AUTOSAR XML (schema 4-2-2)
package /STELLANTIS/EPT/ASWCs
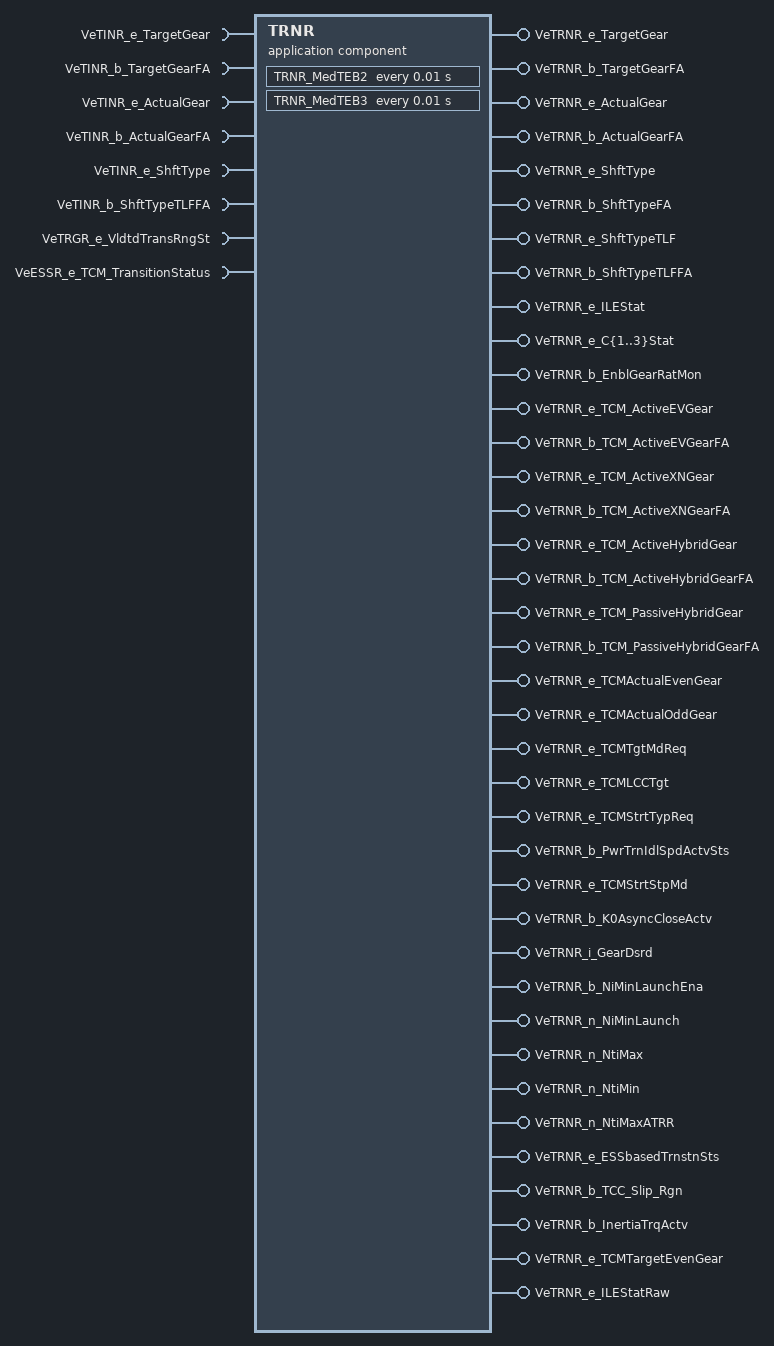
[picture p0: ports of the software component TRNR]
  application sw component type TRNR
    8 x require port:
      VeTINR_e_TargetGear: variation-point={short-label=vpVeTINR_e_TargetGear, sw-syscond=1}, nonqueued-receiver-com-spec{data-element=Value, init-value=CeTRNR_e_Neutral}, required-interface=VeTINR_e_TargetGear
      VeTINR_b_TargetGearFA: variation-point={short-label=vpVeTINR_b_TargetGearFA, sw-syscond=1}, nonqueued-receiver-com-spec{data-element=Value, init-value=0}, required-interface=VeTINR_b_TargetGearFA
      VeTINR_e_ActualGear: variation-point={short-label=vpVeTINR_e_ActualGear, sw-syscond=1}, nonqueued-receiver-com-spec{data-element=Value, init-value=CeTRNR_e_Neutral}, required-interface=VeTINR_e_ActualGear
      VeTINR_b_ActualGearFA: variation-point={short-label=vpVeTINR_b_ActualGearFA, sw-syscond=1}, nonqueued-receiver-com-spec{data-element=Value, init-value=0}, required-interface=VeTINR_b_ActualGearFA
      VeTINR_e_ShftType: variation-point={short-label=vpVeTINR_e_ShftType, sw-syscond=1}, nonqueued-receiver-com-spec{data-element=Value, init-value=CeTRNR_e_SteadyState}, required-interface=VeTINR_e_ShftType
      VeTINR_b_ShftTypeTLFFA: nonqueued-receiver-com-spec{data-element=Value, init-value=0}, required-interface=VeTINR_b_ShftTypeTLFFA
      VeTRGR_e_VldtdTransRngSt: variation-point={short-label=vpVeTRGR_e_VldtdTransRngSt, sw-syscond=1}, nonqueued-receiver-com-spec{data-element=Value, init-value=CeTRGR_e_NoSelectionAvailable}, required-interface=VeTRGR_e_VldtdTransRngSt
      VeESSR_e_TCM_TransitionStatus: nonqueued-receiver-com-spec{data-element=Value, init-value=CeESSR_e_Trans_Stat_Off}, required-interface=VeESSR_e_TCM_TransitionStatus
    40 x provide port:
      VeTRNR_e_TargetGear: nonqueued-sender-com-spec{data-element=Value, init-value=CeTRNR_e_Neutral}, provided-interface=VeTRNR_e_TargetGear
      VeTRNR_b_TargetGearFA: nonqueued-sender-com-spec{data-element=Value, init-value=0}, provided-interface=VeTRNR_b_TargetGearFA
      VeTRNR_e_ActualGear: nonqueued-sender-com-spec{data-element=Value, init-value=CeTRNR_e_Neutral}, provided-interface=VeTRNR_e_ActualGear
      VeTRNR_b_ActualGearFA: nonqueued-sender-com-spec{data-element=Value, init-value=0}, provided-interface=VeTRNR_b_ActualGearFA
      VeTRNR_e_ShftType: nonqueued-sender-com-spec{data-element=Value, init-value=CeTRNR_e_SteadyState}, provided-interface=VeTRNR_e_ShftType
      VeTRNR_b_ShftTypeFA: nonqueued-sender-com-spec{data-element=Value, init-value=0}, provided-interface=VeTRNR_b_ShftTypeFA
      VeTRNR_e_ShftTypeTLF: nonqueued-sender-com-spec{data-element=Value, init-value=CeTRNR_e_SteadyStateDCT}, provided-interface=VeTRNR_e_ShftTypeTLF
      VeTRNR_b_ShftTypeTLFFA: nonqueued-sender-com-spec{data-element=Value, init-value=0}, provided-interface=VeTRNR_b_ShftTypeTLFFA
      VeTRNR_e_ILEStat: nonqueued-sender-com-spec{data-element=Value, init-value=CeHCCR_e_ClInvalid}, provided-interface=VeTRNR_e_ILEStat
      VeTRNR_e_C{1..3}Stat: nonqueued-sender-com-spec{data-element=Value, init-value=CeHCCR_e_ClInvalid}, provided-interface=VeTRNR_e_C{1..3}Stat
      VeTRNR_b_EnblGearRatMon: nonqueued-sender-com-spec{data-element=Value, init-value=0}, provided-interface=VeTRNR_b_EnblGearRatMon
      VeTRNR_e_TCM_ActiveEVGear: nonqueued-sender-com-spec{data-element=Value, init-value=CeTRNR_e_Neutral}, provided-interface=VeTRNR_e_TCM_ActiveEVGear
      VeTRNR_b_TCM_ActiveEVGearFA: nonqueued-sender-com-spec{data-element=Value, init-value=0}, provided-interface=VeTRNR_b_TCM_ActiveEVGearFA
      VeTRNR_e_TCM_ActiveXNGear: nonqueued-sender-com-spec{data-element=Value, init-value=CeTRNR_e_Neutral}, provided-interface=VeTRNR_e_TCM_ActiveXNGear
      VeTRNR_b_TCM_ActiveXNGearFA: nonqueued-sender-com-spec{data-element=Value, init-value=0}, provided-interface=VeTRNR_b_TCM_ActiveXNGearFA
      VeTRNR_e_TCM_ActiveHybridGear: nonqueued-sender-com-spec{data-element=Value, init-value=CeTRNR_e_Neutral}, provided-interface=VeTRNR_e_TCM_ActiveHybridGear
      VeTRNR_b_TCM_ActiveHybridGearFA: nonqueued-sender-com-spec{data-element=Value, init-value=0}, provided-interface=VeTRNR_b_TCM_ActiveHybridGearFA
      VeTRNR_e_TCM_PassiveHybridGear: nonqueued-sender-com-spec{data-element=Value, init-value=CeTRNR_e_Neutral}, provided-interface=VeTRNR_e_TCM_PassiveHybridGear
      VeTRNR_b_TCM_PassiveHybridGearFA: nonqueued-sender-com-spec{data-element=Value, init-value=0}, provided-interface=VeTRNR_b_TCM_PassiveHybridGearFA
      VeTRNR_e_TCMActualEvenGear: nonqueued-sender-com-spec{data-element=Value, init-value=CeTRNR_e_Neutral}, provided-interface=VeTRNR_e_TCMActualEvenGear
      VeTRNR_e_TCMActualOddGear: nonqueued-sender-com-spec{data-element=Value, init-value=CeTRNR_e_Neutral}, provided-interface=VeTRNR_e_TCMActualOddGear
      VeTRNR_e_TCMTgtMdReq: nonqueued-sender-com-spec{data-element=Value, init-value=CeTRNR_e_SerEngOff}, provided-interface=VeTRNR_e_TCMTgtMdReq
      VeTRNR_e_TCMLCCTgt: nonqueued-sender-com-spec{data-element=Value, init-value=CeTMMR_e_ClchUnlock}, provided-interface=VeTRNR_e_TCMLCCTgt
      VeTRNR_e_TCMStrtTypReq: nonqueued-sender-com-spec{data-element=Value, init-value=CeTRNR_e_NormalStrt}, provided-interface=VeTRNR_e_TCMStrtTypReq
      VeTRNR_b_PwrTrnIdlSpdActvSts: nonqueued-sender-com-spec{data-element=Value, init-value=0}, provided-interface=VeTRNR_b_PwrTrnIdlSpdActvSts
      VeTRNR_e_TCMStrtStpMd: nonqueued-sender-com-spec{data-element=Value, init-value=CeTRNR_e_TCMStrtStpMd_inactv}, provided-interface=VeTRNR_e_TCMStrtStpMd
      VeTRNR_b_K0AsyncCloseActv: nonqueued-sender-com-spec{data-element=Value, init-value=0}, provided-interface=VeTRNR_b_K0AsyncCloseActv
      VeTRNR_i_GearDsrd: nonqueued-sender-com-spec{data-element=Value, init-value=0}, provided-interface=VeTRNR_i_GearDsrd
      VeTRNR_b_NiMinLaunchEna: nonqueued-sender-com-spec{data-element=Value, init-value=0}, provided-interface=VeTRNR_b_NiMinLaunchEna
      VeTRNR_n_NiMinLaunch: nonqueued-sender-com-spec{data-element=Value, init-value=0}, provided-interface=VeTRNR_n_NiMinLaunch
      VeTRNR_n_NtiMax: nonqueued-sender-com-spec{data-element=Value, init-value=0}, provided-interface=VeTRNR_n_NtiMax
      VeTRNR_n_NtiMin: nonqueued-sender-com-spec{data-element=Value, init-value=0}, provided-interface=VeTRNR_n_NtiMin
      VeTRNR_n_NtiMaxATRR: nonqueued-sender-com-spec{data-element=Value, init-value=0}, provided-interface=VeTRNR_n_NtiMaxATRR
      VeTRNR_e_ESSbasedTrnstnSts: nonqueued-sender-com-spec{data-element=Value, init-value=CeESSR_e_Trans_Stat_Off}, provided-interface=VeTRNR_e_ESSbasedTrnstnSts
      VeTRNR_b_TCC_Slip_Rgn: nonqueued-sender-com-spec{data-element=Value, init-value=0}, provided-interface=VeTRNR_b_TCC_Slip_Rgn
      VeTRNR_b_InertiaTrqActv: nonqueued-sender-com-spec{data-element=Value, init-value=0}, provided-interface=VeTRNR_b_InertiaTrqActv
      VeTRNR_e_TCMTargetEvenGear: nonqueued-sender-com-spec{data-element=Value, init-value=CeTRNR_e_Neutral}, provided-interface=VeTRNR_e_TCMTargetEvenGear
      VeTRNR_e_ILEStatRaw: nonqueued-sender-com-spec{data-element=Value, init-value=CeHCCR_e_ClInvalid}, provided-interface=VeTRNR_e_ILEStatRaw
    behavior IB_TRNR: data-type-mapping=msADTtoIDTMapping, handle-termination-and-restart=NO-SUPPORT, included-data-type-set=data-type=rt_Array_TeTRNR_e_TCMGearStat_4
      timing event Event_MedTEB2: start-on-event=TRNR_MedTEB2, period=0.01
      timing event Event_MedTEB3: start-on-event=TRNR_MedTEB3, period=0.01
      init event Event_TRNR_ac_Init: start-on-event=TRNR_ac_Init
      init event Event_PwrOn: start-on-event=TRNR_PwrOn
      explicit-inter-runnable-variables:
        data TRNC_C2_StatInternal_IRV: category=VALUE, sw-calibration-access=READ-ONLY, type=TeHCCR_e_ClutchStatus, init-value=CeHCCR_e_ClInvalid
      4 x runnable:
        TRNR_ac_Init
          data-send-points:
            22 x access:
              OUT_VeTRNR_b_TCC_Slip_Rgn_Value: accessed-variable=VeTRNR_b_TCC_Slip_Rgn.Value
              OUT_VeTRNR_e_TargetGear_Value: accessed-variable=VeTRNR_e_TargetGear.Value
              OUT_VeTRNR_e_ActualGear_Value: accessed-variable=VeTRNR_e_ActualGear.Value
              OUT_VeTRNR_e_ShftType_Value: accessed-variable=VeTRNR_e_ShftType.Value
              OUT_VeTRNR_e_ShftTypeTLF_Value: accessed-variable=VeTRNR_e_ShftTypeTLF.Value
              OUT_VeTRNR_e_ILEStat_Value: accessed-variable=VeTRNR_e_ILEStat.Value
              OUT_VeTRNR_e_C{1..3}Stat_Value: accessed-variable=VeTRNR_e_C{1..3}Stat.Value
              OUT_VeTRNR_e_TCM_ActiveEVGear_Value: accessed-variable=VeTRNR_e_TCM_ActiveEVGear.Value
              OUT_VeTRNR_e_TCM_ActiveXNGear_Value: accessed-variable=VeTRNR_e_TCM_ActiveXNGear.Value
              OUT_VeTRNR_e_TCM_ActiveHybridGear_Value: accessed-variable=VeTRNR_e_TCM_ActiveHybridGear.Value
              OUT_VeTRNR_e_TCM_PassiveHybridGear_Value: accessed-variable=VeTRNR_e_TCM_PassiveHybridGear.Value
              OUT_VeTRNR_e_TCMActualEvenGear_Value: accessed-variable=VeTRNR_e_TCMActualEvenGear.Value
              OUT_VeTRNR_e_TCMActualOddGear_Value: accessed-variable=VeTRNR_e_TCMActualOddGear.Value
              OUT_VeTRNR_e_TCMTgtMdReq_Value: accessed-variable=VeTRNR_e_TCMTgtMdReq.Value
              OUT_VeTRNR_e_TCMLCCTgt_Value: accessed-variable=VeTRNR_e_TCMLCCTgt.Value
              OUT_VeTRNR_e_TCMStrtTypReq_Value: accessed-variable=VeTRNR_e_TCMStrtTypReq.Value
              OUT_VeTRNR_e_TCMStrtStpMd_Value: accessed-variable=VeTRNR_e_TCMStrtStpMd.Value
              OUT_VeTRNR_e_ESSbasedTrnstnSts_Value: accessed-variable=VeTRNR_e_ESSbasedTrnstnSts.Value
              OUT_VeTRNR_e_TCMTargetEvenGear_Value: accessed-variable=VeTRNR_e_TCMTargetEvenGear.Value
              OUT_VeTRNR_e_ILEStatRaw_Value: accessed-variable=VeTRNR_e_ILEStatRaw.Value
        TRNR_PwrOn
          data-send-points:
            40 x access:
              OUT_VeTRNR_e_C2Stat_Value: accessed-variable=VeTRNR_e_C2Stat.Value
              OUT_VeTRNR_b_TargetGearFA_Value: accessed-variable=VeTRNR_b_TargetGearFA.Value
              OUT_VeTRNR_b_ActualGearFA_Value: accessed-variable=VeTRNR_b_ActualGearFA.Value
              OUT_VeTRNR_i_GearDsrd_Value: accessed-variable=VeTRNR_i_GearDsrd.Value
              OUT_VeTRNR_b_NiMinLaunchEna_Value: accessed-variable=VeTRNR_b_NiMinLaunchEna.Value
              OUT_VeTRNR_n_NiMinLaunch_Value: accessed-variable=VeTRNR_n_NiMinLaunch.Value
              OUT_VeTRNR_e_TCMLCCTgt_Value: accessed-variable=VeTRNR_e_TCMLCCTgt.Value
              OUT_VeTRNR_e_ActualGear_Value: accessed-variable=VeTRNR_e_ActualGear.Value
              OUT_VeTRNR_e_TargetGear_Value: accessed-variable=VeTRNR_e_TargetGear.Value
              OUT_VeTRNR_e_ShftType_Value: accessed-variable=VeTRNR_e_ShftType.Value
              OUT_VeTRNR_n_NtiMax_Value: accessed-variable=VeTRNR_n_NtiMax.Value
              OUT_VeTRNR_e_C1Stat_Value: accessed-variable=VeTRNR_e_C1Stat.Value
              OUT_VeTRNR_n_NtiMin_Value: accessed-variable=VeTRNR_n_NtiMin.Value
              OUT_VeTRNR_b_ShftTypeFA_Value: accessed-variable=VeTRNR_b_ShftTypeFA.Value
              OUT_VeTRNR_e_ILEStat_Value: accessed-variable=VeTRNR_e_ILEStat.Value
              OUT_VeTRNR_b_K0AsyncCloseActv_Value: accessed-variable=VeTRNR_b_K0AsyncCloseActv.Value
              OUT_VeTRNR_b_EnblGearRatMon_Value: accessed-variable=VeTRNR_b_EnblGearRatMon.Value
              OUT_VeTRNR_b_TCM_ActiveEVGearFA_Value: accessed-variable=VeTRNR_b_TCM_ActiveEVGearFA.Value
              OUT_VeTRNR_e_TCM_ActiveHybridGear_Value: accessed-variable=VeTRNR_e_TCM_ActiveHybridGear.Value
              OUT_VeTRNR_e_TCM_ActiveEVGear_Value: accessed-variable=VeTRNR_e_TCM_ActiveEVGear.Value
              OUT_VeTRNR_e_TCM_ActiveXNGear_Value: accessed-variable=VeTRNR_e_TCM_ActiveXNGear.Value
              OUT_VeTRNR_e_TCM_PassiveHybridGear_Value: accessed-variable=VeTRNR_e_TCM_PassiveHybridGear.Value
              OUT_VeTRNR_e_C3Stat_Value: accessed-variable=VeTRNR_e_C3Stat.Value
              OUT_VeTRNR_b_TCM_ActiveXNGearFA_Value: accessed-variable=VeTRNR_b_TCM_ActiveXNGearFA.Value
              OUT_VeTRNR_b_TCM_ActiveHybridGearFA_Value: accessed-variable=VeTRNR_b_TCM_ActiveHybridGearFA.Value
              OUT_VeTRNR_b_TCM_PassiveHybridGearFA_Value: accessed-variable=VeTRNR_b_TCM_PassiveHybridGearFA.Value
              OUT_VeTRNR_e_ESSbasedTrnstnSts_Value: accessed-variable=VeTRNR_e_ESSbasedTrnstnSts.Value
              OUT_VeTRNR_e_TCMActualEvenGear_Value: accessed-variable=VeTRNR_e_TCMActualEvenGear.Value
              OUT_VeTRNR_e_TCMActualOddGear_Value: accessed-variable=VeTRNR_e_TCMActualOddGear.Value
              OUT_VeTRNR_n_NtiMaxATRR_Value: accessed-variable=VeTRNR_n_NtiMaxATRR.Value
              OUT_VeTRNR_b_InertiaTrqActv_Value: accessed-variable=VeTRNR_b_InertiaTrqActv.Value
              OUT_VeTRNR_e_TCMTargetEvenGear_Value: accessed-variable=VeTRNR_e_TCMTargetEvenGear.Value
              OUT_VeTRNR_e_TCMTgtMdReq_Value: accessed-variable=VeTRNR_e_TCMTgtMdReq.Value
              OUT_VeTRNR_e_TCMStrtTypReq_Value: accessed-variable=VeTRNR_e_TCMStrtTypReq.Value
              OUT_VeTRNR_b_PwrTrnIdlSpdActvSts_Value: accessed-variable=VeTRNR_b_PwrTrnIdlSpdActvSts.Value
              OUT_VeTRNR_e_TCMStrtStpMd_Value: accessed-variable=VeTRNR_e_TCMStrtStpMd.Value
              OUT_VeTRNR_b_ShftTypeTLFFA_Value: accessed-variable=VeTRNR_b_ShftTypeTLFFA.Value
              OUT_VeTRNR_e_ShftTypeTLF_Value: accessed-variable=VeTRNR_e_ShftTypeTLF.Value
              OUT_VeTRNR_b_TCC_Slip_Rgn_Value: accessed-variable=VeTRNR_b_TCC_Slip_Rgn.Value
              OUT_VeTRNR_e_ILEStatRaw_Value: accessed-variable=VeTRNR_e_ILEStatRaw.Value
          written-local-variables:
            access WV_TRNC_C2_StatInternal_IRV: accessed-variable=TRNC_C2_StatInternal_IRV
        TRNR_MedTEB2
          data-receive-point-by-arguments:
            8 x access:
              IN_VeESSR_e_TCM_TransitionStatus_Value: accessed-variable=VeESSR_e_TCM_TransitionStatus.Value
              IN_VeTINR_b_ActualGearFA_Value: accessed-variable=VeTINR_b_ActualGearFA.Value, variation-point={short-label=vpIN_VeTINR_b_ActualGearFA_Value, sw-syscond=1}
              IN_VeTINR_b_ShftTypeTLFFA_Value: accessed-variable=VeTINR_b_ShftTypeTLFFA.Value
              IN_VeTINR_b_TargetGearFA_Value: accessed-variable=VeTINR_b_TargetGearFA.Value, variation-point={short-label=vpIN_VeTINR_b_TargetGearFA_Value, sw-syscond=1}
              IN_VeTINR_e_ActualGear_Value: accessed-variable=VeTINR_e_ActualGear.Value, variation-point={short-label=vpIN_VeTINR_e_ActualGear_Value, sw-syscond=1}
              IN_VeTINR_e_ShftType_Value: accessed-variable=VeTINR_e_ShftType.Value, variation-point={short-label=vpIN_VeTINR_e_ShftType_Value, sw-syscond=1}
              IN_VeTINR_e_TargetGear_Value: accessed-variable=VeTINR_e_TargetGear.Value, variation-point={short-label=vpIN_VeTINR_e_TargetGear_Value, sw-syscond=1}
              IN_VeTRGR_e_VldtdTransRngSt_Value: accessed-variable=VeTRGR_e_VldtdTransRngSt.Value, variation-point={short-label=vpIN_VeTRGR_e_VldtdTransRngSt_Value, sw-syscond=1}
          data-send-points:
            26 x access:
              OUT_VeTRNR_e_ESSbasedTrnstnSts_Value: accessed-variable=VeTRNR_e_ESSbasedTrnstnSts.Value
              OUT_VeTRNR_b_ShftTypeTLFFA_Value: accessed-variable=VeTRNR_b_ShftTypeTLFFA.Value
              OUT_VeTRNR_b_TCM_ActiveEVGearFA_Value: accessed-variable=VeTRNR_b_TCM_ActiveEVGearFA.Value
              OUT_VeTRNR_b_TCM_ActiveHybridGearFA_Value: accessed-variable=VeTRNR_b_TCM_ActiveHybridGearFA.Value
              OUT_VeTRNR_b_TCM_ActiveXNGearFA_Value: accessed-variable=VeTRNR_b_TCM_ActiveXNGearFA.Value
              OUT_VeTRNR_b_ActualGearFA_Value: accessed-variable=VeTRNR_b_ActualGearFA.Value
              OUT_VeTRNR_b_EnblGearRatMon_Value: accessed-variable=VeTRNR_b_EnblGearRatMon.Value
              OUT_VeTRNR_b_TCM_PassiveHybridGearFA_Value: accessed-variable=VeTRNR_b_TCM_PassiveHybridGearFA.Value
              OUT_VeTRNR_b_ShftTypeFA_Value: accessed-variable=VeTRNR_b_ShftTypeFA.Value
              OUT_VeTRNR_b_TargetGearFA_Value: accessed-variable=VeTRNR_b_TargetGearFA.Value
              OUT_VeTRNR_e_ActualGear_Value: accessed-variable=VeTRNR_e_ActualGear.Value
              OUT_VeTRNR_e_ILEStatRaw_Value: accessed-variable=VeTRNR_e_ILEStatRaw.Value
              OUT_VeTRNR_e_ShftType_Value: accessed-variable=VeTRNR_e_ShftType.Value
              OUT_VeTRNR_e_ShftTypeTLF_Value: accessed-variable=VeTRNR_e_ShftTypeTLF.Value
              OUT_VeTRNR_e_TargetGear_Value: accessed-variable=VeTRNR_e_TargetGear.Value
              OUT_VeTRNR_e_TCM_ActiveEVGear_Value: accessed-variable=VeTRNR_e_TCM_ActiveEVGear.Value
              OUT_VeTRNR_e_TCM_ActiveHybridGear_Value: accessed-variable=VeTRNR_e_TCM_ActiveHybridGear.Value
              OUT_VeTRNR_e_TCM_ActiveXNGear_Value: accessed-variable=VeTRNR_e_TCM_ActiveXNGear.Value
              OUT_VeTRNR_e_TCM_PassiveHybridGear_Value: accessed-variable=VeTRNR_e_TCM_PassiveHybridGear.Value
              OUT_VeTRNR_e_TCMActualEvenGear_Value: accessed-variable=VeTRNR_e_TCMActualEvenGear.Value
              OUT_VeTRNR_e_TCMActualOddGear_Value: accessed-variable=VeTRNR_e_TCMActualOddGear.Value
              OUT_VeTRNR_e_TCMTargetEvenGear_Value: accessed-variable=VeTRNR_e_TCMTargetEvenGear.Value
              OUT_VeTRNR_e_ILEStat_Value: accessed-variable=VeTRNR_e_ILEStat.Value
              OUT_VeTRNR_e_C{1..3}Stat_Value: accessed-variable=VeTRNR_e_C{1..3}Stat.Value
        TRNR_MedTEB3
          data-receive-point-by-arguments:
            access IN_VeTRGR_e_VldtdTransRngSt_Value: accessed-variable=VeTRGR_e_VldtdTransRngSt.Value, variation-point={short-label=vpIN_VeTRGR_e_VldtdTransRngSt_Value, sw-syscond=1}
          data-send-points:
            13 x access:
              OUT_VeTRNR_b_InertiaTrqActv_Value: accessed-variable=VeTRNR_b_InertiaTrqActv.Value
              OUT_VeTRNR_b_K0AsyncCloseActv_Value: accessed-variable=VeTRNR_b_K0AsyncCloseActv.Value
              OUT_VeTRNR_b_NiMinLaunchEna_Value: accessed-variable=VeTRNR_b_NiMinLaunchEna.Value
              OUT_VeTRNR_b_PwrTrnIdlSpdActvSts_Value: accessed-variable=VeTRNR_b_PwrTrnIdlSpdActvSts.Value
              OUT_VeTRNR_e_TCMLCCTgt_Value: accessed-variable=VeTRNR_e_TCMLCCTgt.Value
              OUT_VeTRNR_e_TCMStrtStpMd_Value: accessed-variable=VeTRNR_e_TCMStrtStpMd.Value
              OUT_VeTRNR_e_TCMStrtTypReq_Value: accessed-variable=VeTRNR_e_TCMStrtTypReq.Value
              OUT_VeTRNR_e_TCMTgtMdReq_Value: accessed-variable=VeTRNR_e_TCMTgtMdReq.Value
              OUT_VeTRNR_i_GearDsrd_Value: accessed-variable=VeTRNR_i_GearDsrd.Value
              OUT_VeTRNR_n_NiMinLaunch_Value: accessed-variable=VeTRNR_n_NiMinLaunch.Value
              OUT_VeTRNR_n_NtiMax_Value: accessed-variable=VeTRNR_n_NtiMax.Value
              OUT_VeTRNR_n_NtiMaxATRR_Value: accessed-variable=VeTRNR_n_NtiMaxATRR.Value
              OUT_VeTRNR_n_NtiMin_Value: accessed-variable=VeTRNR_n_NtiMin.Value
      16 x variation point proxy, all with category=CONDITION:
        Variant_TRNR_ClutchStatPostProcess: condition-access=0
        Variant_TRNR_Clutch_Status: condition-access=0
        Variant_TRNR_DisbClutchStatPostProcess: condition-access=1
        Variant_TRNR_EnbPostC1: condition-access=0
        Variant_TRNR_EnbPostC2: condition-access=0
        Variant_TRNR_EnbPostILE: condition-access=0
        Variant_TRNR_GearDsrd: condition-access=0
        Variant_TRNR_HSERActGear: condition-access=0
        Variant_TRNR_IdlSpdActvSts: condition-access=0
        Variant_TRNR_InertTrqActv: condition-access=0
        Variant_TRNR_LaunchCntrl: condition-access=0
        Variant_TRNR_NtiMinMax: condition-access=0
        Variant_TRNR_SelTgtActGear: condition-access=1
        Variant_TRNR_ShftTypeArb: condition-access=0
        Variant_TRNR_TCMStrtStpMd: condition-access=0
        Variant_TRNR_TgtAndStrt: condition-access=0
